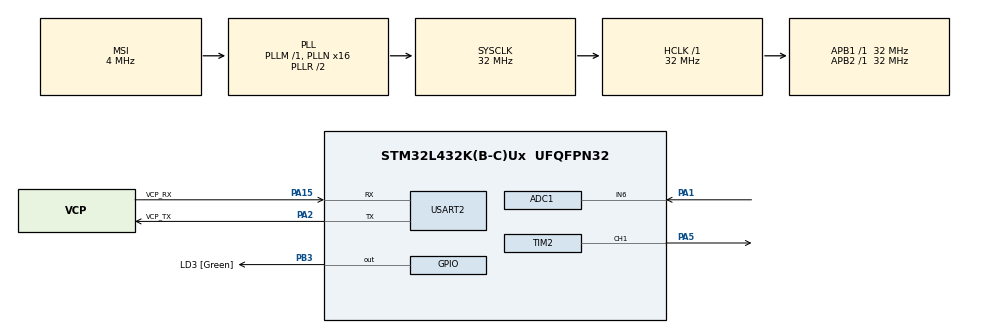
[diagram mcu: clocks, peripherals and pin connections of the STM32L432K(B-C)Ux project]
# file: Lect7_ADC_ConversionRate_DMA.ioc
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ADC1.Channel-0\#ChannelRegularConversion=ADC_CHANNEL_6
ADC1.ContinuousConvMode=ENABLE
ADC1.DMAContinuousRequests=ENABLE
ADC1.NbrOfConversionFlag=1
ADC1.OffsetNumber-0\#ChannelRegularConversion=ADC_OFFSET_NONE
ADC1.Rank-0\#ChannelRegularConversion=1
ADC1.SamplingTime-0\#ChannelRegularConversion=ADC_SAMPLETIME_2CYCLES_5
ADC1.master=1
Dma.ADC1.0.Direction=DMA_PERIPH_TO_MEMORY
Dma.ADC1.0.Instance=DMA1_Channel1
Dma.ADC1.0.MemDataAlignment=DMA_MDATAALIGN_HALFWORD
Dma.ADC1.0.MemInc=DMA_MINC_ENABLE
Dma.ADC1.0.Mode=DMA_NORMAL
Dma.ADC1.0.PeriphDataAlignment=DMA_PDATAALIGN_HALFWORD
Dma.ADC1.0.PeriphInc=DMA_PINC_DISABLE
Dma.ADC1.0.Priority=DMA_PRIORITY_LOW
Dma.Request0=ADC1
Mcu.Family=STM32L4
Mcu.Name=STM32L432K(B-C)Ux
Mcu.Package=UFQFPN32
NVIC.DMA1_Channel1_IRQn=true\:0\:0\:false\:false\:true\:false\:true
NVIC.PriorityGroup=NVIC_PRIORITYGROUP_4
PA0.GPIO_Label=MCO [High speed clock in]
PA0.Mode=HSE-External-Clock-Source-for-LittleOrca
PA0.Signal=RCC_CK_IN
PA1.Signal=ADCx_IN6
PA13\ (JTMS-SWDIO).GPIO_Label=SWDIO
PA13\ (JTMS-SWDIO).Mode=Serial_Wire
PA13\ (JTMS-SWDIO).Signal=SYS_JTMS-SWDIO
PA14\ (JTCK-SWCLK).GPIO_Label=SWCLK
PA14\ (JTCK-SWCLK).Mode=Serial_Wire
PA14\ (JTCK-SWCLK).Signal=SYS_JTCK-SWCLK
PA15\ (JTDI).GPIO_Label=VCP_RX
PA15\ (JTDI).Mode=Asynchronous
PA15\ (JTDI).Signal=USART2_RX
PA2.GPIO_Label=VCP_TX
PA2.Mode=Asynchronous
PA2.Signal=USART2_TX
PA5.Signal=S_TIM2_CH1
PB3\ (JTDO-TRACESWO).GPIO_Label=LD3 [Green]
PB3\ (JTDO-TRACESWO).Signal=GPIO_Output
PC14-OSC32_IN\ (PC14).Mode=LSE-External-Oscillator
PC14-OSC32_IN\ (PC14).Signal=RCC_OSC32_IN
PC15-OSC32_OUT\ (PC15).Mode=LSE-External-Oscillator
PC15-OSC32_OUT\ (PC15).Signal=RCC_OSC32_OUT
ProjectManager.HeapSize=0x200
ProjectManager.StackSize=0x400
ProjectManager.TargetToolchain=STM32CubeIDE
RCC.ADCFreq_Value=32000000
RCC.AHBFreq_Value=32000000
RCC.APB1Freq_Value=32000000
RCC.APB1TimFreq_Value=32000000
RCC.APB2Freq_Value=32000000
RCC.APB2TimFreq_Value=32000000
RCC.CortexFreq_Value=32000000
RCC.HCLKFreq_Value=32000000
RCC.HSE_VALUE=8000000
RCC.HSI16_VALUE=16000000
RCC.HSI48_VALUE=48000000
RCC.HSI_VALUE=16000000
RCC.MSI_VALUE=4000000
RCC.PLLMUL=RCC_PLLMUL_4
RCC.PLLN=16
RCC.PLLSAI1N=16
RCC.SYSCLKFreq_VALUE=32000000
RCC.SYSCLKSource=RCC_SYSCLKSOURCE_PLLCLK
RCC.USBFreq_Value=32000000
RCC.VCOOutputFreq_Value=64000000
SH.ADCx_IN6.0=ADC1_IN6,IN6-Single-Ended
SH.S_TIM2_CH1.0=TIM2_CH1,PWM Generation1 CH1
TIM2.Channel-PWM\ Generation1\ CH1=TIM_CHANNEL_1
TIM2.Period=3199
TIM2.Pulse-PWM\ Generation1\ CH1=1599
USART2.VirtualMode-Asynchronous=VM_ASYNC
VP_TIM2_VS_ClockSourceINT.Mode=Internal
board=NUCLEO-L432KC

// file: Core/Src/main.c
/* USER CODE BEGIN Header */
/**
  ******************************************************************************
  * @file           : main.c
  * @brief          : Main program body
  ******************************************************************************
  * @attention
  *
  * <h2><center>&copy; Copyright (c) 2020 STMicroelectronics.
  * All rights reserved.</center></h2>
  *
  * This software component is licensed by ST under BSD 3-Clause license,
  * the "License"; You may not use this file except in compliance with the
  * License. You may obtain a copy of the License at:
  *                        opensource.org/licenses/BSD-3-Clause
  *
  ******************************************************************************
  */
/* USER CODE END Header */
#include "main.h"

/* USER CODE BEGIN Includes */
#define ADC_BUF_LEN 4096

/* USER CODE END Includes */

ADC_HandleTypeDef hadc1;
DMA_HandleTypeDef hdma_adc1;

TIM_HandleTypeDef htim2;

UART_HandleTypeDef huart2;

/* USER CODE BEGIN PV */
uint16_t adc_buf[ADC_BUF_LEN];
/* USER CODE END PV */

void SystemClock_Config(void);
static void MX_GPIO_Init(void);
static void MX_DMA_Init(void);
static void MX_USART2_UART_Init(void);
static void MX_ADC1_Init(void);
static void MX_TIM2_Init(void);

int main(void)
{

  /* MCU Configuration--------------------------------------------------------*/

  /* Reset of all peripherals, Initializes the Flash interface and the Systick. */
  HAL_Init();

  /* Configure the system clock */
  SystemClock_Config();

  /* Initialize all configured peripherals */
  MX_GPIO_Init();
  MX_DMA_Init();
  MX_USART2_UART_Init();
  MX_ADC1_Init();
  MX_TIM2_Init();
  /* USER CODE BEGIN 2 */
  HAL_TIM_PWM_Start(&htim2,  TIM_CHANNEL_1);
   HAL_Delay(500);
   HAL_ADC_Start_DMA(&hadc1, (uint32_t *)adc_buf, ADC_BUF_LEN);

  /* USER CODE END 2 */

  /* Infinite loop */
  while (1)
  {

  }
}

void SystemClock_Config(void)
{
  RCC_OscInitTypeDef RCC_OscInitStruct = {0};
  RCC_ClkInitTypeDef RCC_ClkInitStruct = {0};
  RCC_PeriphCLKInitTypeDef PeriphClkInit = {0};

  /** Configure LSE Drive Capability
  */
  HAL_PWR_EnableBkUpAccess();
  __HAL_RCC_LSEDRIVE_CONFIG(RCC_LSEDRIVE_LOW);
  /** Initializes the RCC Oscillators according to the specified parameters
  * in the RCC_OscInitTypeDef structure.
  */
  RCC_OscInitStruct.OscillatorType = RCC_OSCILLATORTYPE_LSE|RCC_OSCILLATORTYPE_MSI;
  RCC_OscInitStruct.LSEState = RCC_LSE_ON;
  RCC_OscInitStruct.MSIState = RCC_MSI_ON;
  RCC_OscInitStruct.MSICalibrationValue = 0;
  RCC_OscInitStruct.MSIClockRange = RCC_MSIRANGE_6;
  RCC_OscInitStruct.PLL.PLLState = RCC_PLL_ON;
  RCC_OscInitStruct.PLL.PLLSource = RCC_PLLSOURCE_MSI;
  RCC_OscInitStruct.PLL.PLLM = 1;
  RCC_OscInitStruct.PLL.PLLN = 16;
  RCC_OscInitStruct.PLL.PLLP = RCC_PLLP_DIV7;
  RCC_OscInitStruct.PLL.PLLQ = RCC_PLLQ_DIV2;
  RCC_OscInitStruct.PLL.PLLR = RCC_PLLR_DIV2;
  if (HAL_RCC_OscConfig(&RCC_OscInitStruct) != HAL_OK)
  {
    Error_Handler();
  }
  /** Initializes the CPU, AHB and APB buses clocks
  */
  RCC_ClkInitStruct.ClockType = RCC_CLOCKTYPE_HCLK|RCC_CLOCKTYPE_SYSCLK
                              |RCC_CLOCKTYPE_PCLK1|RCC_CLOCKTYPE_PCLK2;
  RCC_ClkInitStruct.SYSCLKSource = RCC_SYSCLKSOURCE_PLLCLK;
  RCC_ClkInitStruct.AHBCLKDivider = RCC_SYSCLK_DIV1;
  RCC_ClkInitStruct.APB1CLKDivider = RCC_HCLK_DIV1;
  RCC_ClkInitStruct.APB2CLKDivider = RCC_HCLK_DIV1;

  if (HAL_RCC_ClockConfig(&RCC_ClkInitStruct, FLASH_LATENCY_1) != HAL_OK)
  {
    Error_Handler();
  }
  PeriphClkInit.PeriphClockSelection = RCC_PERIPHCLK_USART2|RCC_PERIPHCLK_ADC;
  PeriphClkInit.Usart2ClockSelection = RCC_USART2CLKSOURCE_PCLK1;
  PeriphClkInit.AdcClockSelection = RCC_ADCCLKSOURCE_PLLSAI1;
  PeriphClkInit.PLLSAI1.PLLSAI1Source = RCC_PLLSOURCE_MSI;
  PeriphClkInit.PLLSAI1.PLLSAI1M = 1;
  PeriphClkInit.PLLSAI1.PLLSAI1N = 16;
  PeriphClkInit.PLLSAI1.PLLSAI1P = RCC_PLLP_DIV7;
  PeriphClkInit.PLLSAI1.PLLSAI1Q = RCC_PLLQ_DIV2;
  PeriphClkInit.PLLSAI1.PLLSAI1R = RCC_PLLR_DIV2;
  PeriphClkInit.PLLSAI1.PLLSAI1ClockOut = RCC_PLLSAI1_ADC1CLK;
  if (HAL_RCCEx_PeriphCLKConfig(&PeriphClkInit) != HAL_OK)
  {
    Error_Handler();
  }
  /** Configure the main internal regulator output voltage
  */
  if (HAL_PWREx_ControlVoltageScaling(PWR_REGULATOR_VOLTAGE_SCALE1) != HAL_OK)
  {
    Error_Handler();
  }
  /** Enable MSI Auto calibration
  */
  HAL_RCCEx_EnableMSIPLLMode();
}

static void MX_ADC1_Init(void)
{

  ADC_ChannelConfTypeDef sConfig = {0};

  /** Common config
  */
  hadc1.Instance = ADC1;
  hadc1.Init.ClockPrescaler = ADC_CLOCK_ASYNC_DIV1;
  hadc1.Init.Resolution = ADC_RESOLUTION_12B;
  hadc1.Init.DataAlign = ADC_DATAALIGN_RIGHT;
  hadc1.Init.ScanConvMode = ADC_SCAN_DISABLE;
  hadc1.Init.EOCSelection = ADC_EOC_SINGLE_CONV;
  hadc1.Init.LowPowerAutoWait = DISABLE;
  hadc1.Init.ContinuousConvMode = ENABLE;
  hadc1.Init.NbrOfConversion = 1;
  hadc1.Init.DiscontinuousConvMode = DISABLE;
  hadc1.Init.ExternalTrigConv = ADC_SOFTWARE_START;
  hadc1.Init.ExternalTrigConvEdge = ADC_EXTERNALTRIGCONVEDGE_NONE;
  hadc1.Init.DMAContinuousRequests = ENABLE;
  hadc1.Init.Overrun = ADC_OVR_DATA_PRESERVED;
  hadc1.Init.OversamplingMode = DISABLE;
  if (HAL_ADC_Init(&hadc1) != HAL_OK)
  {
    Error_Handler();
  }
  /** Configure Regular Channel
  */
  sConfig.Channel = ADC_CHANNEL_6;
  sConfig.Rank = ADC_REGULAR_RANK_1;
  sConfig.SamplingTime = ADC_SAMPLETIME_2CYCLES_5;
  sConfig.SingleDiff = ADC_SINGLE_ENDED;
  sConfig.OffsetNumber = ADC_OFFSET_NONE;
  sConfig.Offset = 0;
  if (HAL_ADC_ConfigChannel(&hadc1, &sConfig) != HAL_OK)
  {
    Error_Handler();
  }

}

static void MX_TIM2_Init(void)
{

  TIM_ClockConfigTypeDef sClockSourceConfig = {0};
  TIM_MasterConfigTypeDef sMasterConfig = {0};
  TIM_OC_InitTypeDef sConfigOC = {0};

  htim2.Instance = TIM2;
  htim2.Init.Prescaler = 0;
  htim2.Init.CounterMode = TIM_COUNTERMODE_UP;
  htim2.Init.Period = 3199;
  htim2.Init.ClockDivision = TIM_CLOCKDIVISION_DIV1;
  htim2.Init.AutoReloadPreload = TIM_AUTORELOAD_PRELOAD_DISABLE;
  if (HAL_TIM_Base_Init(&htim2) != HAL_OK)
  {
    Error_Handler();
  }
  sClockSourceConfig.ClockSource = TIM_CLOCKSOURCE_INTERNAL;
  if (HAL_TIM_ConfigClockSource(&htim2, &sClockSourceConfig) != HAL_OK)
  {
    Error_Handler();
  }
  if (HAL_TIM_PWM_Init(&htim2) != HAL_OK)
  {
    Error_Handler();
  }
  sMasterConfig.MasterOutputTrigger = TIM_TRGO_RESET;
  sMasterConfig.MasterSlaveMode = TIM_MASTERSLAVEMODE_DISABLE;
  if (HAL_TIMEx_MasterConfigSynchronization(&htim2, &sMasterConfig) != HAL_OK)
  {
    Error_Handler();
  }
  sConfigOC.OCMode = TIM_OCMODE_PWM1;
  sConfigOC.Pulse = 1599;
  sConfigOC.OCPolarity = TIM_OCPOLARITY_HIGH;
  sConfigOC.OCFastMode = TIM_OCFAST_DISABLE;
  if (HAL_TIM_PWM_ConfigChannel(&htim2, &sConfigOC, TIM_CHANNEL_1) != HAL_OK)
  {
    Error_Handler();
  }
  HAL_TIM_MspPostInit(&htim2);

}

static void MX_USART2_UART_Init(void)
{

  huart2.Instance = USART2;
  huart2.Init.BaudRate = 115200;
  huart2.Init.WordLength = UART_WORDLENGTH_8B;
  huart2.Init.StopBits = UART_STOPBITS_1;
  huart2.Init.Parity = UART_PARITY_NONE;
  huart2.Init.Mode = UART_MODE_TX_RX;
  huart2.Init.HwFlowCtl = UART_HWCONTROL_NONE;
  huart2.Init.OverSampling = UART_OVERSAMPLING_16;
  huart2.Init.OneBitSampling = UART_ONE_BIT_SAMPLE_DISABLE;
  huart2.AdvancedInit.AdvFeatureInit = UART_ADVFEATURE_NO_INIT;
  if (HAL_UART_Init(&huart2) != HAL_OK)
  {
    Error_Handler();
  }

}

static void MX_DMA_Init(void)
{

  /* DMA controller clock enable */
  __HAL_RCC_DMA1_CLK_ENABLE();

  /* DMA interrupt init */
  /* DMA1_Channel1_IRQn interrupt configuration */
  HAL_NVIC_SetPriority(DMA1_Channel1_IRQn, 0, 0);
  HAL_NVIC_EnableIRQ(DMA1_Channel1_IRQn);

}

static void MX_GPIO_Init(void)
{
  GPIO_InitTypeDef GPIO_InitStruct = {0};

  /* GPIO Ports Clock Enable */
  __HAL_RCC_GPIOC_CLK_ENABLE();
  __HAL_RCC_GPIOA_CLK_ENABLE();
  __HAL_RCC_GPIOB_CLK_ENABLE();

  /*Configure GPIO pin Output Level */
  HAL_GPIO_WritePin(LD3_GPIO_Port, LD3_Pin, GPIO_PIN_RESET);

  /*Configure GPIO pin : LD3_Pin */
  GPIO_InitStruct.Pin = LD3_Pin;
  GPIO_InitStruct.Mode = GPIO_MODE_OUTPUT_PP;
  GPIO_InitStruct.Pull = GPIO_NOPULL;
  GPIO_InitStruct.Speed = GPIO_SPEED_FREQ_LOW;
  HAL_GPIO_Init(LD3_GPIO_Port, &GPIO_InitStruct);

}

/* USER CODE BEGIN 4 */
void HAL_ADC_ConvCpltCallback(ADC_HandleTypeDef* hadc)
{
	char buf[80];
	for(int i=0;i<ADC_BUF_LEN;++i)
	{
		sprintf(buf,"%d,   %d\r\n",i,adc_buf[i]);
		HAL_UART_Transmit(&huart2, buf, strlen(buf), 100);
	}
}

/* USER CODE END 4 */

void Error_Handler(void)
{
}

/************************ (C) COPYRIGHT STMicroelectronics *****END OF FILE****/
